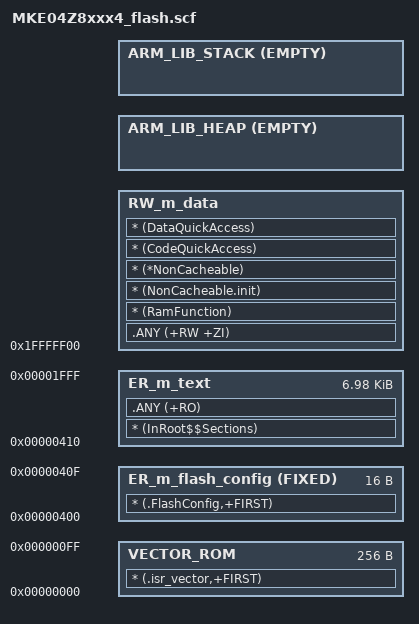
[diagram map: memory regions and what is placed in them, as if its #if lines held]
#!armclang --target=arm-arm-none-eabi -mcpu=cortex-m0plus -E -x c
/*
** ###################################################################
**     Processors:          MKE04Z8VFK4
**                          MKE04Z8VTG4
**                          MKE04Z8VWJ4
**
**     Compiler:            Keil ARM C/C++ Compiler
**     Reference manual:    MKE04P24M48SF0RM Rev 4
**     Version:             rev. 1.0, 2017-05-19
**     Build:               b210812
**
**     Abstract:
**         Linker file for the Keil ARM C/C++ Compiler
**
**     Copyright 2016 Freescale Semiconductor, Inc.
**     Copyright 2016-2021 NXP
**     All rights reserved.
**
**     SPDX-License-Identifier: BSD-3-Clause
**
**     http:                 www.nxp.com
**     mail:                 support@nxp.com
**
** ###################################################################
*/

#define m_interrupts_start             0x00000000
#define m_interrupts_size              0x00000100

#define m_flash_config_start           0x00000400
#define m_flash_config_size            0x00000010

#define m_text_start                   0x00000410
#define m_text_size                    0x00001BF0

#define m_data_start                   0x1FFFFF00
#define m_data_size                    0x00000400

/* Sizes */
#if (defined(__stack_size__))
  #define Stack_Size                   __stack_size__
#else
  #define Stack_Size                   0x0050
#endif

#if (defined(__heap_size__))
  #define Heap_Size                    __heap_size__
#else
  #define Heap_Size                    0x0050
#endif

LR_m_text m_interrupts_start m_text_start+m_text_size-m_interrupts_start { ; load region size_region
  VECTOR_ROM m_interrupts_start m_interrupts_size { ; load address = execution address
    * (.isr_vector,+FIRST)
  }
  ER_m_flash_config m_flash_config_start FIXED m_flash_config_size { ; load address = execution address
    * (.FlashConfig,+FIRST)
  }
  ER_m_text m_text_start m_text_size { ; load address = execution address
    * (InRoot$$Sections)
    .ANY (+RO)
  }

  RW_m_data m_data_start m_data_size-Stack_Size-Heap_Size { ; RW data
    .ANY (+RW +ZI)
    * (RamFunction)
    * (NonCacheable.init)
    * (*NonCacheable)
    * (CodeQuickAccess)
    * (DataQuickAccess)
  }
  ARM_LIB_HEAP +0 EMPTY Heap_Size {    ; Heap region growing up
  }
  ARM_LIB_STACK m_data_start+m_data_size EMPTY -Stack_Size { ; Stack region growing down
  }
}

